# HK32F030xMxxA register map
Vendor: HKMicroChip Ltd.; Series: HK32F030xMxxA; File version: 0.9
CPU: CM0 r0p0, little endian, no MPU, no FPU, 3 interrupt priority bits
Registers are 32-bit, read-write, reset 0x0 unless marked. A register's access mark holds for its fields unless they carry their own. Offsets are from the block's base; [hi:lo] are bit positions.

## RCC
Base 0x40021000
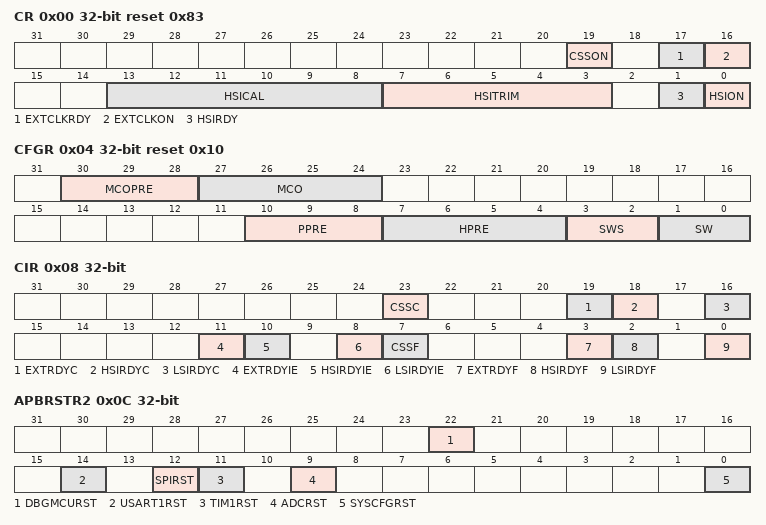
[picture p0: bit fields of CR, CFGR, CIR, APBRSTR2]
0x00 CR access per field reset 0x83
  [19] CSSON rw — Clock Security System enable
  [17] EXTCLKRDY ro — External clock ready flag
  [16] EXTCLKON rw — External clock enable
  [13:8] HSICAL rw — HSI clock calibration
  [7:3] HSITRIM rw — HSI clock trimming
  [1] HSIRDY ro — HSI clock ready flag
  [0] HSION rw — HSI clock enable
0x04 CFGR access per field reset 0x10
  [30:28] MCOPRE rw — Microcontroller clock output prescaler
  [27:24] MCO rw — Microcontroller clock output
  [10:8] PPRE rw — PCLK prescaler
  [7:4] HPRE rw — HCLK prescaler
  [3:2] SWS ro — System clock switch status
  [1:0] SW rw — System clock switch
0x08 CIR access per field
  [23] CSSC wo — Clock security system interrupt clear
  [19] EXTRDYC wo — External clock ready interrupt clear
  [18] HSIRDYC wo — HSI ready interrupt clear
  [16] LSIRDYC wo — LSI ready interrupt clear
  [11] EXTRDYIE rw — External clock ready interrupt enable
  [10] HSIRDYIE rw — HSI ready interrupt enable
  [8] LSIRDYIE rw — LSI ready interrupt enable
  [7] CSSF ro — Clock security system interrupt flag
  [3] EXTRDYF ro — External clock ready interrupt flag
  [2] HSIRDYF ro — HSI ready interrupt flag
  [0] LSIRDYF ro — LSI ready interrupt flag
0x0C APBRSTR2
  [22] DBGMCURST — Debug MCU reset
  [14] USART1RST — Reset USART1
  [12] SPIRST — Reset SPI
  [11] TIM1RST — Reset TIM1 timer
  [9] ADCRST — Reset ADC interface
  [0] SYSCFGRST — Reset SYSCFG
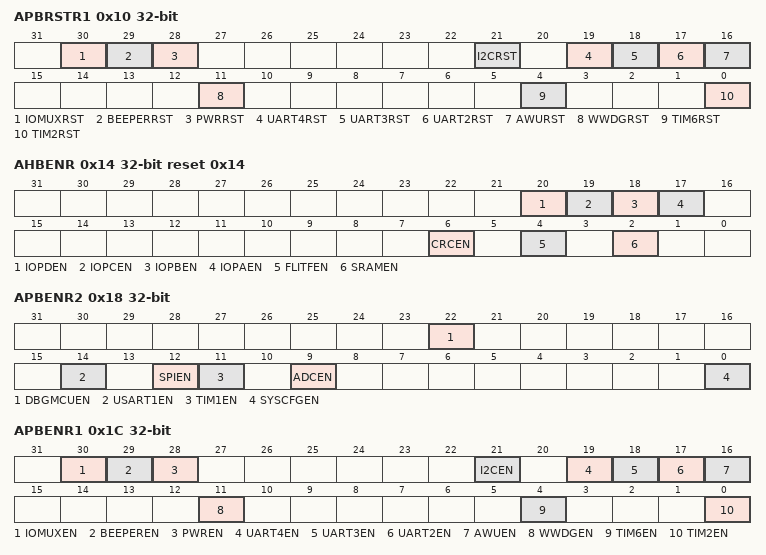
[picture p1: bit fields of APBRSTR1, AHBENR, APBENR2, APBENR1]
0x10 APBRSTR1
  [30] IOMUXRST — Reset IOMUX
  [29] BEEPERRST — Reset Beeper
  [28] PWRRST — Reset power interface
  [21] I2CRST — Reset I2C
  [19] UART4RST — Reset UART4
  [18] UART3RST — Reset UART3
  [17] UART2RST — Reset UART2
  [16] AWURST — Auto_wake up reset in stop mode
  [11] WWDGRST — Reset Window watchdog
  [4] TIM6RST — Reset TIM6 timer
  [0] TIM2RST — Reset TIM2 timer
0x14 AHBENR reset 0x14
  [20] IOPDEN — I/O port D clock enable
  [19] IOPCEN — I/O port C clock enable
  [18] IOPBEN — I/O port B clock enable
  [17] IOPAEN — I/O port A clock enable
  [6] CRCEN — CRC clock enable
  [4] FLITFEN — FLITF clock enable
  [2] SRAMEN — SRAM interface clock enable
0x18 APBENR2
  [22] DBGMCUEN — MCU debug module clock enable
  [14] USART1EN — USART1 clock enable
  [12] SPIEN — SPI clock enable
  [11] TIM1EN — TIM1 timer clock enable
  [9] ADCEN — ADC interface clock enable
  [0] SYSCFGEN — SYSCFG clock enable
0x1C APBENR1
  [30] IOMUXEN — IOMUX clock enable
  [29] BEEPEREN — Beeper clock enable
  [28] PWREN — Power interface clock enable
  [21] I2CEN — I2C clock enable
  [19] UART4EN — UART4 clock enable
  [18] UART3EN — UART3 clock enable
  [17] UART2EN — UART2 clock enable
  [16] AWUEN — Auto-wake up clock enable in stop mode
  [11] WWDGEN — Window watchdog clock enable
  [4] TIM6EN — TIM6 timer clock enable
  [0] TIM2EN — TIM2 timer clock enable
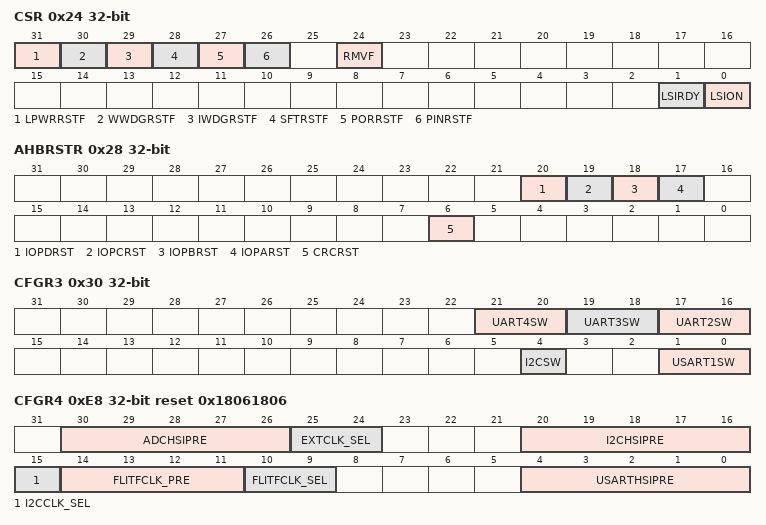
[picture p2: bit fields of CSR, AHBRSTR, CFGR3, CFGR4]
0x24 CSR access per field
  [31] LPWRRSTF ro — Low-power reset flag
  [30] WWDGRSTF ro — Window watchdog reset flag
  [29] IWDGRSTF ro — Independent watchdog reset flag
  [28] SFTRSTF ro — Software reset flag
  [27] PORRSTF ro — POR/PDR reset flag
  [26] PINRSTF ro — PIN reset flag
  [24] RMVF ro — Remove reset flag
  [1] LSIRDY ro — LSI oscillator ready
  [0] LSION rw — LSI oscillator enable
0x28 AHBRSTR
  [20] IOPDRST — Reset I/O port D
  [19] IOPCRST — Reset I/O port C
  [18] IOPBRST — Reset I/O port B
  [17] IOPARST — Reset I/O port A
  [6] CRCRST — Reset CRC
0x30 CFGR3
  [21:20] UART4SW — UART4 clock source selection
  [19:18] UART3SW — UART3 clock source selection
  [17:16] UART2SW — UART2 clock source selection
  [4] I2CSW — I2C clock source selection
  [1:0] USART1SW — USART1 clock source selection
0xE0 CSS reset 0x1E000000
  [31:25] CSS_THRESHOLD — Clock security system threshold value
0xE8 CFGR4 reset 0x18061806
  [30:26] ADCHSIPRE — ADC_HSI prescaler
  [25:24] EXTCLK_SEL — External clock io selection
  [20:16] I2CHSIPRE — I2C_HSI prescaler
  [15] I2CCLK_SEL — I2C clock selection
  [14:11] FLITFCLK_PRE — FLITFCLK prescaler
  [10:9] FLITFCLK_SEL — FLITFCLK clock selection
  [4:0] USARTHSIPRE — USART_HSI prescaler
